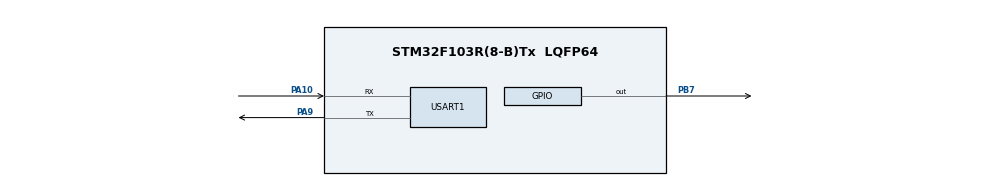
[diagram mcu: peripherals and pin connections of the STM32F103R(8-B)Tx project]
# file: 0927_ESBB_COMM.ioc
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Mcu.Family=STM32F1
Mcu.Name=STM32F103R(8-B)Tx
Mcu.Package=LQFP64
NVIC.PriorityGroup=NVIC_PRIORITYGROUP_4
NVIC.USART1_IRQn=true\:0\:0\:false\:false\:true\:true\:true
PA10.Mode=Asynchronous
PA10.Signal=USART1_RX
PA13.Mode=Serial_Wire
PA13.Signal=SYS_JTMS-SWDIO
PA14.Mode=Serial_Wire
PA14.Signal=SYS_JTCK-SWCLK
PA9.Mode=Asynchronous
PA9.Signal=USART1_TX
PB7.Signal=GPIO_Output
ProjectManager.HeapSize=0x200
ProjectManager.StackSize=0x400
ProjectManager.TargetToolchain=TrueSTUDIO
RCC.APB1Freq_Value=8000000
RCC.APB2Freq_Value=8000000
USART1.VirtualMode=VM_ASYNC
board=custom

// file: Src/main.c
/* USER CODE BEGIN Header */
/**
  ******************************************************************************
  * @file           : main.c
  * @brief          : Main program body
  ******************************************************************************
  * @attention
  *
  * <h2><center>&copy; Copyright (c) 2020 STMicroelectronics.
  * All rights reserved.</center></h2>
  *
  * This software component is licensed by ST under BSD 3-Clause license,
  * the "License"; You may not use this file except in compliance with the
  * License. You may obtain a copy of the License at:
  *                        opensource.org/licenses/BSD-3-Clause
  *
  ******************************************************************************
  */
/* USER CODE END Header */

#include "main.h"

/* USER CODE BEGIN Includes */
#include "comm.h"
/* USER CODE END Includes */

UART_HandleTypeDef huart1;

void SystemClock_Config(void);
static void MX_GPIO_Init(void);
static void MX_USART1_UART_Init(void);

/* USER CODE BEGIN 0 */
uint8_t RxData;

void HAL_UART_RxCpltCallback(UART_HandleTypeDef *huart)
{
	//HAL_UART_Transmit(&huart1, &RxData, sizeof(RxData), 0xFFFFFFFF);
    CommPutRxChar(&CommBuf, RxData);

	HAL_UART_Receive_IT(&huart1, &RxData, sizeof(RxData));

}

int _write(int fd, char *str, int len)
{
 for(int i=0; i<len; i++)
 {
  HAL_UART_Transmit(&huart1, (uint8_t *)&str[i], 1, 0xFFFF);
 }
 return len;
}
/* USER CODE END 0 */

int main(void)
{
  /* USER CODE BEGIN 1 */
  uint8_t data;
  /* USER CODE END 1 */

  /* MCU Configuration--------------------------------------------------------*/

  /* Reset of all peripherals, Initializes the Flash interface and the Systick. */
  HAL_Init();

  /* Configure the system clock */
  SystemClock_Config();

  /* Initialize all configured peripherals */
  MX_GPIO_Init();
  MX_USART1_UART_Init();
  /* USER CODE BEGIN 2 */
  HAL_UART_Receive_IT(&huart1, &RxData, sizeof(RxData));  // USART Rx interrupt enable

  CommInit(&CommBuf);

  /* USER CODE END 2 */

  /* Infinite loop */
  while (1)
  {

    /* USER CODE BEGIN 3 */
	HAL_GPIO_TogglePin(GPIOB, GPIO_PIN_7);
	HAL_Delay(1000);

	while( CommIsEmpty(&CommBuf) == FALSE )
	{
		data = CommGetRxChar(&CommBuf);
		HAL_UART_Transmit(&huart1, &data, sizeof(data), 0xFFFFFFFF);
	}
  }
  /* USER CODE END 3 */
}

void SystemClock_Config(void)
{
  RCC_OscInitTypeDef RCC_OscInitStruct = {0};
  RCC_ClkInitTypeDef RCC_ClkInitStruct = {0};

  /** Initializes the CPU, AHB and APB busses clocks
  */
  RCC_OscInitStruct.OscillatorType = RCC_OSCILLATORTYPE_HSI;
  RCC_OscInitStruct.HSIState = RCC_HSI_ON;
  RCC_OscInitStruct.HSICalibrationValue = RCC_HSICALIBRATION_DEFAULT;
  RCC_OscInitStruct.PLL.PLLState = RCC_PLL_NONE;
  if (HAL_RCC_OscConfig(&RCC_OscInitStruct) != HAL_OK)
  {
    Error_Handler();
  }
  /** Initializes the CPU, AHB and APB busses clocks
  */
  RCC_ClkInitStruct.ClockType = RCC_CLOCKTYPE_HCLK|RCC_CLOCKTYPE_SYSCLK
                              |RCC_CLOCKTYPE_PCLK1|RCC_CLOCKTYPE_PCLK2;
  RCC_ClkInitStruct.SYSCLKSource = RCC_SYSCLKSOURCE_HSI;
  RCC_ClkInitStruct.AHBCLKDivider = RCC_SYSCLK_DIV1;
  RCC_ClkInitStruct.APB1CLKDivider = RCC_HCLK_DIV1;
  RCC_ClkInitStruct.APB2CLKDivider = RCC_HCLK_DIV1;

  if (HAL_RCC_ClockConfig(&RCC_ClkInitStruct, FLASH_LATENCY_0) != HAL_OK)
  {
    Error_Handler();
  }
}

static void MX_USART1_UART_Init(void)
{

  huart1.Instance = USART1;
  huart1.Init.BaudRate = 115200;
  huart1.Init.WordLength = UART_WORDLENGTH_8B;
  huart1.Init.StopBits = UART_STOPBITS_1;
  huart1.Init.Parity = UART_PARITY_NONE;
  huart1.Init.Mode = UART_MODE_TX_RX;
  huart1.Init.HwFlowCtl = UART_HWCONTROL_NONE;
  huart1.Init.OverSampling = UART_OVERSAMPLING_16;
  if (HAL_UART_Init(&huart1) != HAL_OK)
  {
    Error_Handler();
  }

}

static void MX_GPIO_Init(void)
{
  GPIO_InitTypeDef GPIO_InitStruct = {0};

  /* GPIO Ports Clock Enable */
  __HAL_RCC_GPIOA_CLK_ENABLE();
  __HAL_RCC_GPIOB_CLK_ENABLE();

  /*Configure GPIO pin Output Level */
  HAL_GPIO_WritePin(GPIOB, GPIO_PIN_7, GPIO_PIN_RESET);

  /*Configure GPIO pin : PB7 */
  GPIO_InitStruct.Pin = GPIO_PIN_7;
  GPIO_InitStruct.Mode = GPIO_MODE_OUTPUT_PP;
  GPIO_InitStruct.Pull = GPIO_NOPULL;
  GPIO_InitStruct.Speed = GPIO_SPEED_FREQ_LOW;
  HAL_GPIO_Init(GPIOB, &GPIO_InitStruct);

}

void Error_Handler(void)
{
}

/************************ (C) COPYRIGHT STMicroelectronics *****END OF FILE****/
